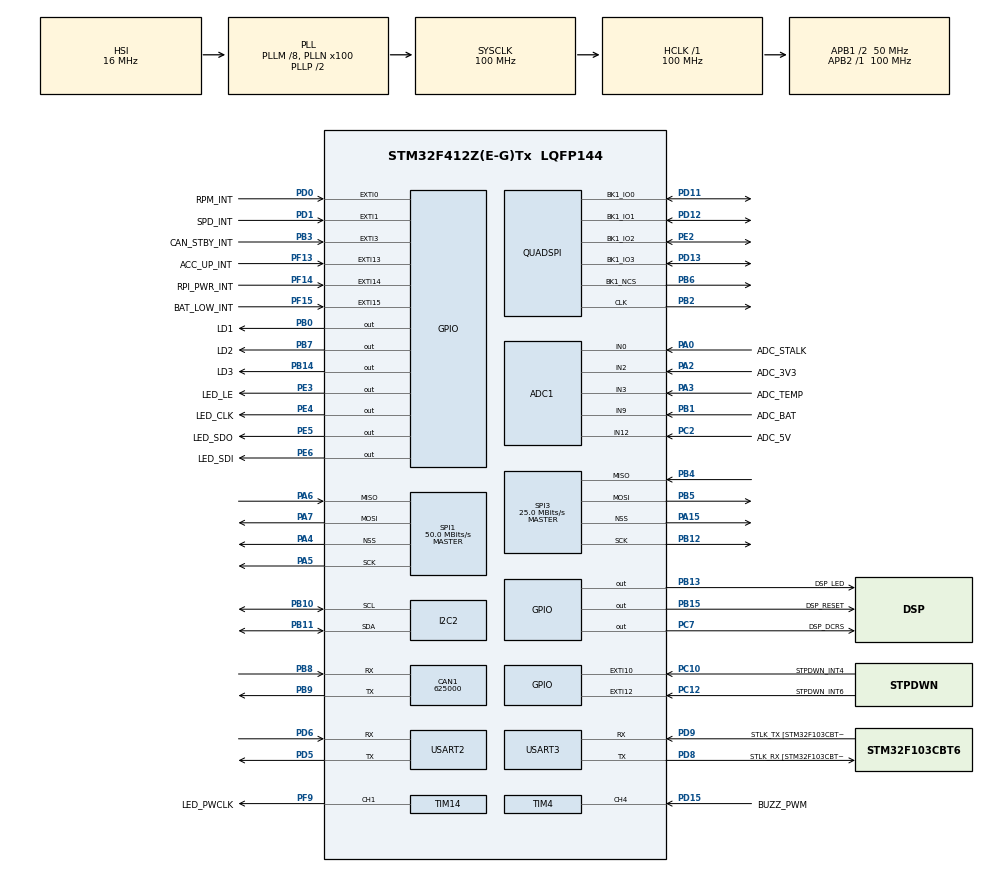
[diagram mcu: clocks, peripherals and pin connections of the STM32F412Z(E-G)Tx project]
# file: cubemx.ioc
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ADC1.Channel-0\#ChannelRegularConversion=ADC_CHANNEL_VREFINT
ADC1.NbrOfConversionFlag=1
ADC1.Rank-0\#ChannelRegularConversion=1
ADC1.SamplingTime-0\#ChannelRegularConversion=ADC_SAMPLETIME_3CYCLES
ADC1.master=1
CAN1.BS1=CAN_BS1_2TQ
CAN1.BS2=CAN_BS2_2TQ
CAN1.CalculateBaudRate=625000
CAN1.CalculateTimeBit=1600
CAN1.CalculateTimeQuantum=320.0
Mcu.Family=STM32F4
Mcu.Name=STM32F412Z(E-G)Tx
Mcu.Package=LQFP144
NVIC.PriorityGroup=NVIC_PRIORITYGROUP_4
NVIC.TIM7_IRQn=true\:15\:0\:false\:false\:true\:false\:true\:true
NVIC.TimeBase=TIM7_IRQn
NVIC.TimeBaseIP=TIM7
PA0.GPIO_Label=ADC_STALK
PA0.Signal=ADCx_IN0
PA13.GPIO_Label=TMS
PA13.Mode=Serial_Wire
PA13.Signal=SYS_JTMS-SWDIO
PA14.GPIO_Label=TCK
PA14.Mode=Serial_Wire
PA14.Signal=SYS_JTCK-SWCLK
PA15.Mode=NSS_Signal_Hard_Output
PA15.Signal=SPI3_NSS
PA2.GPIO_Label=ADC_3V3
PA2.Signal=ADCx_IN2
PA3.GPIO_Label=ADC_TEMP
PA3.Signal=ADCx_IN3
PA4.Mode=NSS_Signal_Hard_Output
PA4.Signal=SPI1_NSS
PA5.Mode=Full_Duplex_Master
PA5.Signal=SPI1_SCK
PA6.Mode=Full_Duplex_Master
PA6.Signal=SPI1_MISO
PA7.Mode=Full_Duplex_Master
PA7.Signal=SPI1_MOSI
PB0.GPIO_Label=LD1
PB0.Signal=GPIO_Output
PB1.GPIO_Label=ADC_BAT
PB1.Signal=ADCx_IN9
PB10.Mode=I2C
PB10.Signal=I2C2_SCL
PB11.Mode=I2C
PB11.Signal=I2C2_SDA
PB12.Mode=Full_Duplex_Master
PB12.Signal=SPI3_SCK
PB13.GPIO_Label=DSP_LED
PB13.Signal=GPIO_Output
PB14.GPIO_Label=LD3
PB14.Signal=GPIO_Output
PB15.GPIO_Label=DSP_RESET
PB15.Signal=GPIO_Output
PB2.Mode=Single Bank 1
PB2.Signal=QUADSPI_CLK
PB3.GPIO_Label=CAN_STBY_INT
PB3.Signal=GPXTI3
PB4.Mode=Full_Duplex_Master
PB4.Signal=SPI3_MISO
PB5.Mode=Full_Duplex_Master
PB5.Signal=SPI3_MOSI
PB6.Mode=Single Bank 1
PB6.Signal=QUADSPI_BK1_NCS
PB7.GPIO_Label=LD2
PB7.Signal=GPIO_Output
PB8.Mode=CAN_Activate
PB8.Signal=CAN1_RX
PB9.Mode=CAN_Activate
PB9.Signal=CAN1_TX
PC10.GPIO_Label=STPDWN_INT4
PC10.Signal=GPXTI10
PC11.GPIO_Label=STPDWN_INT5
PC11.Signal=EVENTOUT
PC12.GPIO_Label=STPDWN_INT6
PC12.Signal=GPXTI12
PC14-OSC32_IN.Mode=LSE-External-Oscillator
PC14-OSC32_IN.Signal=RCC_OSC32_IN
PC15-OSC32_OUT.Mode=LSE-External-Oscillator
PC15-OSC32_OUT.Signal=RCC_OSC32_OUT
PC2.GPIO_Label=ADC_5V
PC2.Signal=ADCx_IN12
PC7.GPIO_Label=DSP_DCRS
PC7.Signal=GPIO_Output
PD0.GPIO_Label=RPM_INT
PD0.Signal=GPXTI0
PD1.GPIO_Label=SPD_INT
PD1.Signal=GPXTI1
PD11.Mode=Single Bank 1
PD11.Signal=QUADSPI_BK1_IO0
PD12.Mode=Single Bank 1
PD12.Signal=QUADSPI_BK1_IO1
PD13.Mode=Single Bank 1
PD13.Signal=QUADSPI_BK1_IO3
PD15.GPIO_Label=BUZZ_PWM
PD15.Signal=S_TIM4_CH4
PD5.Mode=Asynchronous
PD5.Signal=USART2_TX
PD6.Mode=Asynchronous
PD6.Signal=USART2_RX
PD8.GPIO_Label=STLK_RX [STM32F103CBT6_PA3]
PD8.Mode=Asynchronous
PD8.Signal=USART3_TX
PD9.GPIO_Label=STLK_TX [STM32F103CBT6_PA2]
PD9.Mode=Asynchronous
PD9.Signal=USART3_RX
PE2.Mode=Single Bank 1
PE2.Signal=QUADSPI_BK1_IO2
PE3.GPIO_Label=LED_LE
PE3.Signal=GPIO_Output
PE4.GPIO_Label=LED_CLK
PE4.Signal=GPIO_Output
PE5.GPIO_Label=LED_SDO
PE5.Signal=GPIO_Output
PE6.GPIO_Label=LED_SDI
PE6.Signal=GPIO_Output
PF13.GPIO_Label=ACC_UP_INT
PF13.Signal=GPXTI13
PF14.GPIO_Label=RPI_PWR_INT
PF14.Signal=GPXTI14
PF15.GPIO_Label=BAT_LOW_INT
PF15.Signal=GPXTI15
PF9.GPIO_Label=LED_PWCLK
PF9.Signal=S_TIM14_CH1
PH0\ -\ OSC_IN.GPIO_Label=MCO
PH0\ -\ OSC_IN.Mode=HSE-External-Clock-Source
PH0\ -\ OSC_IN.Signal=RCC_OSC_IN
PH1\ -\ OSC_OUT.Mode=HSE-External-Clock-Source
PH1\ -\ OSC_OUT.Signal=RCC_OSC_OUT
ProjectManager.HeapSize=0x200
ProjectManager.StackSize=0x400
ProjectManager.TargetToolchain=CMake
RCC.48MHZClocksFreq_Value=24000000
RCC.AHBFreq_Value=100000000
RCC.APB1CLKDivider=RCC_HCLK_DIV2
RCC.APB1Freq_Value=50000000
RCC.APB1TimFreq_Value=100000000
RCC.APB2Freq_Value=100000000
RCC.APB2TimFreq_Value=100000000
RCC.CortexFreq_Value=100000000
RCC.HCLKFreq_Value=100000000
RCC.HSE_VALUE=8000000
RCC.HSI_VALUE=16000000
RCC.PLLM=8
RCC.PLLMUL=RCC_PLL_MUL9
RCC.PLLN=100
RCC.PLLQ=8
RCC.PRESCALERUSB=RCC_USBCLKSOURCE_PLL_DIV1_5
RCC.SYSCLKFreq_VALUE=100000000
RCC.SYSCLKSource=RCC_SYSCLKSOURCE_PLLCLK
RCC.SYSCLKSourceVirtual=RCC_SYSCLKSOURCE_PLLCLK
RCC.USBFreq_Value=25000000
RCC.VCOOutputFreq_Value=200000000
SH.ADCx_IN0.0=ADC1_IN0,IN0
SH.ADCx_IN12.0=ADC1_IN12,IN12
SH.ADCx_IN2.0=ADC1_IN2,IN2
SH.ADCx_IN3.0=ADC1_IN3,IN3
SH.ADCx_IN9.0=ADC1_IN9,IN9
SH.S_TIM14_CH1.0=TIM14_CH1,PWM Generation1 CH1
SH.S_TIM4_CH4.0=TIM4_CH4,Input_Capture4_from_TI4
SPI1.BaudRatePrescaler=SPI_BAUDRATEPRESCALER_2
SPI1.CalculateBaudRate=50.0 MBits/s
SPI1.Direction=SPI_DIRECTION_2LINES
SPI1.Mode=SPI_MODE_MASTER
SPI1.VirtualNSS=VM_NSSHARD
SPI1.VirtualType=VM_MASTER
SPI3.CalculateBaudRate=25.0 MBits/s
SPI3.Direction=SPI_DIRECTION_2LINES
SPI3.Mode=SPI_MODE_MASTER
SPI3.VirtualNSS=VM_NSSHARD
SPI3.VirtualType=VM_MASTER
TIM14.Channel=TIM_CHANNEL_1
TIM4.Channel-Input_Capture4_from_TI4=TIM_CHANNEL_4
USART2.VirtualMode=VM_ASYNC
USART3.VirtualMode=VM_ASYNC
VP_ADC1_TempSens_Input.Mode=IN-TempSens
VP_ADC1_Vref_Input.Mode=IN-Vrefint
VP_RTC_VS_RTC_Activate.Mode=RTC_Enabled
VP_SYS_VS_tim7.Mode=TIM7
VP_TIM14_VS_ClockSourceINT.Mode=Enable_Timer
board=NUCLEO-F412ZG

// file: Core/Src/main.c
/* USER CODE BEGIN Header */
/**
  ******************************************************************************
  * @file           : main.c
  * @brief          : Main program body
  ******************************************************************************
  * @attention
  *
  * Copyright (c) 2026 STMicroelectronics.
  * All rights reserved.
  *
  * This software is licensed under terms that can be found in the LICENSE file
  * in the root directory of this software component.
  * If no LICENSE file comes with this software, it is provided AS-IS.
  *
  ******************************************************************************
  */
/* USER CODE END Header */
#include "main.h"
#include "adc.h"
#include "can.h"
#include "i2c.h"
#include "quadspi.h"
#include "rtc.h"
#include "spi.h"
#include "tim.h"
#include "usart.h"
#include "gpio.h"

void SystemClock_Config(void);
/* USER CODE BEGIN PFP */
void my_main();
/* USER CODE END PFP */

int main(void)
{

  /* MCU Configuration--------------------------------------------------------*/

  /* Reset of all peripherals, Initializes the Flash interface and the Systick. */
  HAL_Init();

  /* Configure the system clock */
  SystemClock_Config();

  /* Initialize all configured peripherals */
  MX_GPIO_Init();
  MX_USART2_UART_Init();
  MX_USART3_UART_Init();
  MX_CAN1_Init();
  MX_I2C2_Init();
  MX_SPI1_Init();
  MX_ADC1_Init();
  MX_QUADSPI_Init();
  MX_RTC_Init();
  MX_TIM4_Init();
  MX_TIM14_Init();
  MX_SPI3_Init();

  /* Infinite loop */
  /* USER CODE BEGIN WHILE */
  my_main();
  while (1)
  {
    /* USER CODE END WHILE */

  }
}

void SystemClock_Config(void)
{
  RCC_OscInitTypeDef RCC_OscInitStruct = {0};
  RCC_ClkInitTypeDef RCC_ClkInitStruct = {0};

  /** Configure the main internal regulator output voltage
  */
  __HAL_RCC_PWR_CLK_ENABLE();
  __HAL_PWR_VOLTAGESCALING_CONFIG(PWR_REGULATOR_VOLTAGE_SCALE1);

  /** Initializes the RCC Oscillators according to the specified parameters
  * in the RCC_OscInitTypeDef structure.
  */
  RCC_OscInitStruct.OscillatorType = RCC_OSCILLATORTYPE_HSI|RCC_OSCILLATORTYPE_LSI;
  RCC_OscInitStruct.LSEState = RCC_LSE_ON;
  RCC_OscInitStruct.HSIState = RCC_HSI_ON;
  RCC_OscInitStruct.HSICalibrationValue = RCC_HSICALIBRATION_DEFAULT;
  RCC_OscInitStruct.LSIState = RCC_LSI_ON;
  RCC_OscInitStruct.PLL.PLLState = RCC_PLL_ON;
  RCC_OscInitStruct.PLL.PLLSource = RCC_PLLSOURCE_HSI;
  RCC_OscInitStruct.PLL.PLLM = 8;
  RCC_OscInitStruct.PLL.PLLN = 100;
  RCC_OscInitStruct.PLL.PLLP = RCC_PLLP_DIV2;
  RCC_OscInitStruct.PLL.PLLQ = 8;
  RCC_OscInitStruct.PLL.PLLR = 2;
  if (HAL_RCC_OscConfig(&RCC_OscInitStruct) != HAL_OK)
  {
    Error_Handler();
  }

  /** Initializes the CPU, AHB and APB buses clocks
  */
  RCC_ClkInitStruct.ClockType = RCC_CLOCKTYPE_HCLK|RCC_CLOCKTYPE_SYSCLK
                              |RCC_CLOCKTYPE_PCLK1|RCC_CLOCKTYPE_PCLK2;
  RCC_ClkInitStruct.SYSCLKSource = RCC_SYSCLKSOURCE_PLLCLK;
  RCC_ClkInitStruct.AHBCLKDivider = RCC_SYSCLK_DIV1;
  RCC_ClkInitStruct.APB1CLKDivider = RCC_HCLK_DIV2;
  RCC_ClkInitStruct.APB2CLKDivider = RCC_HCLK_DIV1;

  if (HAL_RCC_ClockConfig(&RCC_ClkInitStruct, FLASH_LATENCY_3) != HAL_OK)
  {
    Error_Handler();
  }
}

void HAL_TIM_PeriodElapsedCallback(TIM_HandleTypeDef *htim)
{
  if (htim->Instance == TIM7)
  {
    HAL_IncTick();
  }
}

void Error_Handler(void)
{
  __disable_irq();
  while (1)
  {
  }
}
